# ATtiny861 device description
Architecture: AVR8; Family: tinyAVR
Registers are 8-bit, access not given, no defined reset value unless marked. A register's access mark holds for its fields unless they carry their own. Offsets are from the block's base; [hi:lo] are bit positions.

## WDT — Watchdog Timer
Instances: WDT 0x00
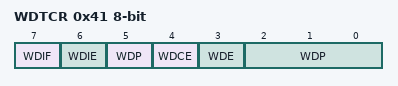
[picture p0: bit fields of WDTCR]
0x41 WDTCR — Watchdog Timer Control Register
  [7] WDIF — Watchdog Timeout Interrupt Flag
  [6] WDIE — Watchdog Timeout Interrupt Enable
  [4] WDCE — Watchdog Change Enable
  [3] WDE — Watch Dog Enable
  [5,2:0] WDP — Watchdog Timer Prescaler Bits
    0=OSCILLATOR_CYCLES_2K; 1=OSCILLATOR_CYCLES_4K; 2=OSCILLATOR_CYCLES_8K; 3=OSCILLATOR_CYCLES_16K; 4=OSCILLATOR_CYCLES_32K; 5=OSCILLATOR_CYCLES_64K; 6=OSCILLATOR_CYCLES_128K; 7=OSCILLATOR_CYCLES_256K; 8=OSCILLATOR_CYCLES_512K; 9=OSCILLATOR_CYCLES_1024K

## TC0 (TC8 module) — Timer/Counter, 8-bit
Instances: TC0 0x00
0x32 OCR0B — Timer/Counter0 Output Compare Register
0x33 OCR0A — Timer/Counter0 Output Compare Register
0x34 TCNT0H — Timer/Counter0 High
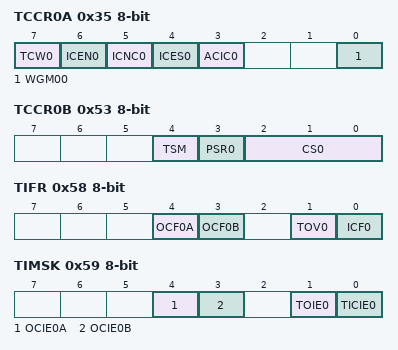
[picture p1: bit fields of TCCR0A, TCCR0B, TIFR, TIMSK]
0x35 TCCR0A — Timer/Counter Control Register A
  [7] TCW0 — Timer/Counter 0 Width
  [6] ICEN0 — Input Capture Mode Enable
  [5] ICNC0 — Input Capture Noise Canceler
  [4] ICES0 — Input Capture Edge Select
  [3] ACIC0 — Analog Comparator Input Capture Enable
  [0] WGM00 — Waveform Generation Mode
0x52 TCNT0L — Timer/Counter0 Low
0x53 TCCR0B — Timer/Counter Control Register B
  [4] TSM — Timer/Counter Synchronization Mode
  [3] PSR0 — Timer/Counter 0 Prescaler Reset
  [2:0] CS0 — Clock Select
    0=NO_CLOCK_SOURCE_STOPPED; 1=RUNNING_NO_PRESCALING; 2=RUNNING_CLK_8; 3=RUNNING_CLK_64; 4=RUNNING_CLK_256; 5=RUNNING_CLK_1024; 6=RUNNING_EXTCLK_TN_FALLING_EDGE; 7=RUNNING_EXTCLK_TN_RISING_EDGE
0x58 TIFR — Timer/Counter0 Interrupt Flag register
  [4] OCF0A — Timer/Counter0 Output Compare Flag 0A
  [3] OCF0B — Timer/Counter0 Output Compare Flag 0B
  [1] TOV0 — Timer/Counter0 Overflow Flag
  [0] ICF0 — Timer/Counter0 Input Capture Flag
0x59 TIMSK — Timer/Counter Interrupt Mask Register
  [4] OCIE0A — Timer/Counter0 Output Compare Match A Interrupt Enable
  [3] OCIE0B — Timer/Counter0 Output Compare Match B Interrupt Enable
  [1] TOIE0 — Timer/Counter0 Overflow Interrupt Enable
  [0] TICIE0 — Timer/Counter0 Input Capture Interrupt Enable

## TC1 (TC16 module) — Timer/Counter, 16-bit
Instances: TC1 0x00
0x20 TCCR1E — Timer/Counter1 Control Register E
  [5:0] OC1OE — Output Compare Override Enable Bits
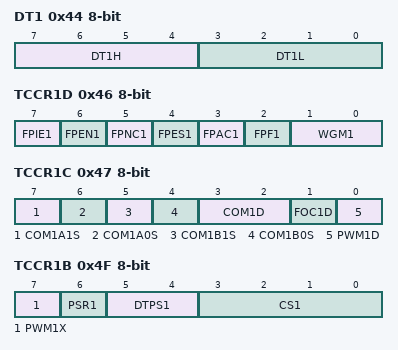
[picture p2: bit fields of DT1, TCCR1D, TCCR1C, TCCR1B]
0x44 DT1 — Timer/Counter 1 Dead Time Value
  [7:4] DT1H, [3:0] DT1L
0x45 TC1H bits used 1:0 — Timer/Counter 1 Register High
0x46 TCCR1D — Timer/Counter Control Register D
  [7] FPIE1 — Fault Protection Interrupt Enable
  [6] FPEN1 — Fault Protection Mode Enable
  [5] FPNC1 — Fault Protection Noise Canceler
  [4] FPES1 — Fault Protection Edge Select
  [3] FPAC1 — Fault Protection Analog Comparator Enable
  [2] FPF1 — Fault Protection Interrupt Flag
  [1:0] WGM1 — Waveform Generation Mode Bit
    0=FAST_PWM_NB_PWMX_MUST_BE_SET; 1=PHASE_AND_FREQUENCY_CORRECT_PWM; 2=PWM6_SINGLE_SLOPE; 3=PWM6_DUAL_SLOPE
0x47 TCCR1C — Timer/Counter Control Register C
  [7] COM1A1S — COM1A1 Shadow Bit
  [6] COM1A0S — COM1A0 Shadow Bit
  [5] COM1B1S — COM1B1 Shadow Bit
  [4] COM1B0S — COM1B0 Shadow Bit
  [3:2] COM1D — Comparator D output mode
  [1] FOC1D — Force Output Compare Match 1D
  [0] PWM1D — Pulse Width Modulator D Enable
0x4A OCR1D — Output compare register
0x4B OCR1C — Output compare register
0x4C OCR1B — Output Compare Register
0x4D OCR1A — Output Compare Register
0x4E TCNT1 — Timer/Counter Register
0x4F TCCR1B — Timer/Counter Control Register B
  [7] PWM1X — PWM Inversion Mode
  [6] PSR1 — Timer/Counter 1 Prescaler reset
  [5:4] DTPS1 — Dead Time Prescaler
    0=1X; 1=2X; 2=4X; 3=8X
  [3:0] CS1 — Clock Select Bits
    0=NO_CLOCK_SOURCE_STOPPED; 1=RUNNING_NO_PRESCALING; 2=RUNNING_CLK_2; 3=RUNNING_CLK_4; 4=RUNNING_CLK_8; 5=RUNNING_CLK_16; 6=RUNNING_CLK_32; 7=RUNNING_CLK_64; 8=RUNNING_CLK_128; 9=RUNNING_CLK_256; 10=RUNNING_CLK_512; 11=RUNNING_CLK_1024; 12=RUNNING_CLK_2048; 13=RUNNING_CLK_4096; 14=RUNNING_CLK_8192; 15=RUNNING_CLK_16384
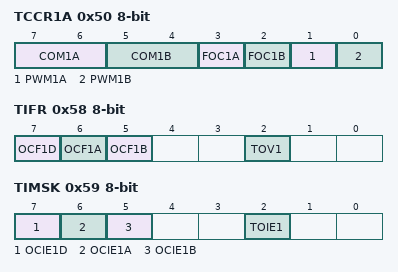
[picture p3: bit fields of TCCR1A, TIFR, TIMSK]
0x50 TCCR1A — Timer/Counter Control Register A
  [7:6] COM1A — Compare Output Mode, Bits
  [5:4] COM1B — Compare Output Mode, Bits
  [3] FOC1A — Force Output Compare Match 1A
  [2] FOC1B — Force Output Compare Match 1B
  [1] PWM1A — Pulse Width Modulator Enable
  [0] PWM1B — Pulse Width Modulator Enable
0x58 TIFR — Timer/Counter Interrupt Flag Register
  [7] OCF1D — Timer/Counter1 Output Compare Flag 1D
  [6] OCF1A — Timer/Counter1 Output Compare Flag 1A
  [5] OCF1B — Timer/Counter1 Output Compare Flag 1B
  [2] TOV1 — Timer/Counter1 Overflow Flag
0x59 TIMSK — Timer/Counter Interrupt Mask Register
  [7] OCIE1D — OCIE1D: Timer/Counter1 Output Compare Interrupt Enable
  [6] OCIE1A — OCIE1A: Timer/Counter1 Output Compare Interrupt Enable
  [5] OCIE1B — OCIE1A: Timer/Counter1 Output Compare B Interrupt Enable
  [2] TOIE1 — Timer/Counter1 Overflow Interrupt Enable

## BOOT_LOAD — Bootloader
Instances: BOOT_LOAD 0x00
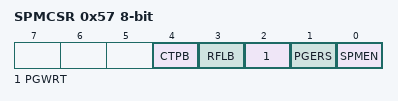
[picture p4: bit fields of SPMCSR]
0x57 SPMCSR — Store Program Memory Control Register
  [4] CTPB — Clear temporary page buffer
  [3] RFLB — Read fuse and lock bits
  [2] PGWRT — Page Write
  [1] PGERS — Page Erase
  [0] SPMEN — Store Program Memory Enable

## EXINT — External Interrupts
Instances: EXINT 0x00
0x42 PCMSK1 — Pin Change Enable Mask 1
0x43 PCMSK0 — Pin Change Enable Mask 0
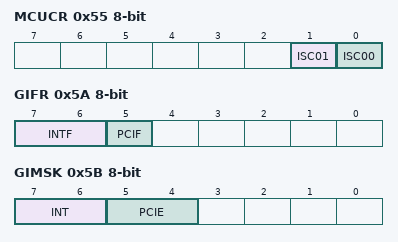
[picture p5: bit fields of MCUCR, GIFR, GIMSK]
0x55 MCUCR — MCU Control Register
  [1] ISC01 — Interrupt Sense Control 0 Bit 1
  [0] ISC00 — Interrupt Sense Control 0 Bit 0
    0=LOW_LEVEL_OF_INTX; 1=ANY_LOGICAL_CHANGE_OF_INTX; 2=FALLING_EDGE_OF_INTX; 3=RISING_EDGE_OF_INTX
0x5A GIFR — General Interrupt Flag register
  [7:6] INTF — External Interrupt Flags
  [5] PCIF — Pin Change Interrupt Flag
0x5B GIMSK — General Interrupt Mask Register
  [7:6] INT — External Interrupt Request 1 Enable
  [5:4] PCIE — Pin Change Interrupt Enables

## CPU — CPU Registers
Instances: CPU 0x00
0x2A GPIOR0 — General purpose register 0
0x2B GPIOR1 — General Purpose register 1
0x2C GPIOR2 — General Purpose IO register 2
0x40 DWDR — debugWire data register
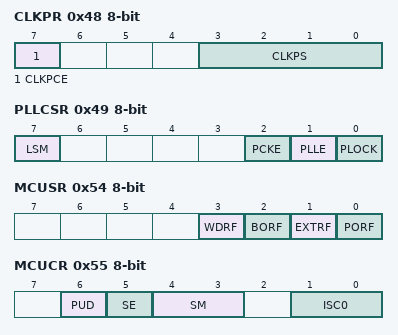
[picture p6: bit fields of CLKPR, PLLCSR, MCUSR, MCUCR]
0x48 CLKPR — Clock Prescale Register
  [7] CLKPCE — Clock Prescaler Change Enable
  [3:0] CLKPS — Clock Prescaler Select Bits
    0=1; 1=2; 2=4; 3=8; 4=16; 5=32; 6=64; 7=128; 8=256
0x49 PLLCSR — PLL Control and status register
  [7] LSM — Low speed mode
  [2] PCKE — PCK Enable
  [1] PLLE — PLL Enable
  [0] PLOCK — PLL Lock detector
0x51 OSCCAL — Oscillator Calibration Register
  [7:0] OSCCAL — Oscillator Calibration
0x54 MCUSR — MCU Status register
  [3] WDRF — Watchdog Reset Flag
  [2] BORF — Brown-out Reset Flag
  [1] EXTRF — External Reset Flag
  [0] PORF — Power-On Reset Flag
0x55 MCUCR — MCU Control Register
  [6] PUD — Pull-up Disable
  [5] SE — Sleep Enable
  [4:3] SM — Sleep Mode Select Bits
    0=IDLE; 1=ADC (ADC Noise Reduction (If Available)); 2=PDOWN (Power Down); 3=STDBY (Standby)
  [1:0] ISC0 — Interrupt Sense Control 0 bits
    0=LOW_LEVEL_OF_INTX; 1=ANY_LOGICAL_CHANGE_IN_INTX; 2=FALLING_EDGE_OF_INTX; 3=RISING_EDGE_OF_INTX
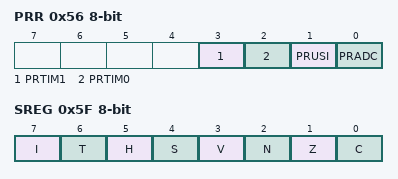
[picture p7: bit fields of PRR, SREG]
0x56 PRR — Power Reduction Register
  [3] PRTIM1 — Power Reduction Timer/Counter1
  [2] PRTIM0 — Power Reduction Timer/Counter0
  [1] PRUSI — Power Reduction USI
  [0] PRADC — Power Reduction ADC
0x5D SP 16-bit bits used 9:0 — Stack Pointer Bytes
0x5F SREG — Status Register
  [7] I — Global Interrupt Enable
  [6] T — Bit Copy Storage
  [5] H — Half Carry Flag
  [4] S — Sign Bit
  [3] V — Two's Complement Overflow Flag
  [2] N — Negative Flag
  [1] Z — Zero Flag
  [0] C — Carry Flag
Value list OSCCAL_VALUE_ADDRESSES: 0=8_0_MHz
